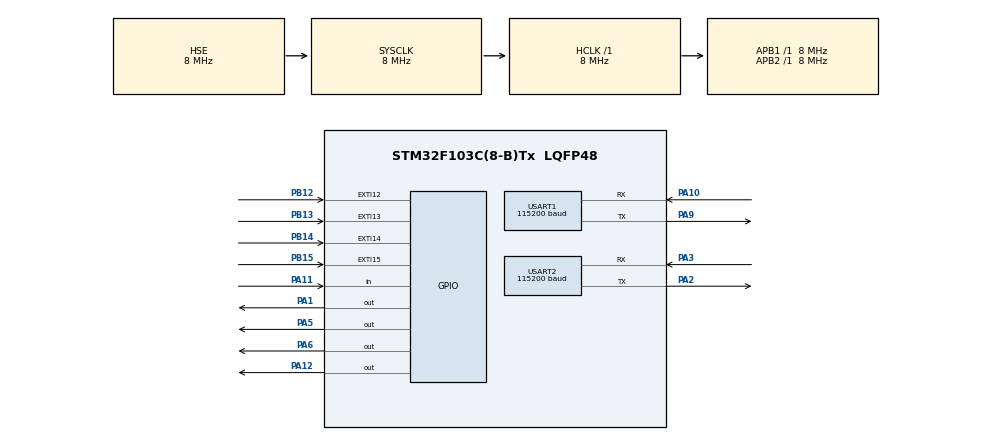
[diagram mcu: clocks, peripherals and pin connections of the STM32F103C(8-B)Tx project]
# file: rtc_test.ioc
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Mcu.Family=STM32F1
Mcu.Name=STM32F103C(8-B)Tx
Mcu.Package=LQFP48
NVIC.EXTI15_10_IRQn=true\:0\:0\:false
NVIC.PriorityGroup=NVIC_PRIORITYGROUP_4
NVIC.TIM2_IRQn=true\:0\:0\:false
NVIC.TIM3_IRQn=true\:0\:0\:false
NVIC.USART1_IRQn=true\:0\:0\:false
NVIC.USART2_IRQn=true\:1\:0\:true
PA1.Signal=GPIO_Output
PA10.GPIO_PuPd=GPIO_NOPULL
PA10.Mode=Asynchronous
PA10.Signal=USART1_RX
PA11.GPIO_PuPd=GPIO_PULLUP
PA11.Signal=GPIO_Input
PA12.GPIO_Speed=GPIO_SPEED_HIGH
PA12.Signal=GPIO_Output
PA2.Mode=Asynchronous
PA2.Signal=USART2_TX
PA3.GPIO_PuPd=GPIO_PULLUP
PA3.Mode=Asynchronous
PA3.Signal=USART2_RX
PA5.Signal=GPIO_Output
PA6.Signal=GPIO_Output
PA9.Mode=Asynchronous
PA9.Signal=USART1_TX
PB12.GPIO_PuPd=GPIO_PULLUP
PB12.Signal=GPXTI12
PB13.GPIO_PuPd=GPIO_PULLUP
PB13.Signal=GPXTI13
PB14.GPIO_PuPd=GPIO_PULLUP
PB14.Signal=GPXTI14
PB15.GPIO_PuPd=GPIO_PULLUP
PB15.Signal=GPXTI15
PC14-OSC32_IN.Mode=LSE-External-Oscillator
PC14-OSC32_IN.Signal=RCC_OSC32_IN
PC15-OSC32_OUT.Mode=LSE-External-Oscillator
PC15-OSC32_OUT.Signal=RCC_OSC32_OUT
PD0-OSC_IN.Mode=HSE-External-Oscillator
PD0-OSC_IN.Signal=RCC_OSC_IN
PD1-OSC_OUT.Mode=HSE-External-Oscillator
PD1-OSC_OUT.Signal=RCC_OSC_OUT
ProjectManager.TargetToolchain=EWARM
RCC.AHBFreq_Value=8000000
RCC.APB1Freq_Value=8000000
RCC.APB1TimFreq_Value=8000000
RCC.APB2Freq_Value=8000000
RCC.APB2TimFreq_Value=8000000
RCC.HCLKFreq_Value=8000000
RCC.HSIState=RCC_HSI_ON
RCC.PLLMUL=RCC_PLL_MUL9
RCC.PLLSourceVirtual=RCC_PLLSOURCE_HSE
RCC.RTCClockSelection=RCC_RTCCLKSOURCE_LSE
RCC.SYSCLKFreq_VALUE=8000000
RCC.SYSCLKSource=RCC_SYSCLKSOURCE_HSE
RCC.USBFreq_Value=72000000
TIM2.Period=4999
TIM2.Prescaler=7999
TIM2.TIM_MasterOutputTrigger=TIM_TRGO_UPDATE
TIM3.Period=1
TIM3.Prescaler=7999
TIM3.TIM_MasterOutputTrigger=TIM_TRGO_UPDATE
USART1.BaudRate=115200
USART2.BaudRate=115200
USART2.Parity=UART_PARITY_NONE
USART2.WordLength=UART_WORDLENGTH_8B
VP_RTC_No_RTC_Output.Mode=RTC OUT
VP_TIM2_VS_ClockSourceINT.Mode=Internal
VP_TIM3_VS_ClockSourceINT.Mode=Internal
board=rtc_test

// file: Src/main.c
/**
  ******************************************************************************
  * File Name          : main.c
  * Description        : Main program body
  ******************************************************************************
  *
  * COPYRIGHT(c) 2016 STMicroelectronics
  *
  * Redistribution and use in source and binary forms, with or without modification,
  * are permitted provided that the following conditions are met:
  *   1. Redistributions of source code must retain the above copyright notice,
  *      this list of conditions and the following disclaimer.
  *   2. Redistributions in binary form must reproduce the above copyright notice,
  *      this list of conditions and the following disclaimer in the documentation
  *      and/or other materials provided with the distribution.
  *   3. Neither the name of STMicroelectronics nor the names of its contributors
  *      may be used to endorse or promote products derived from this software
  *      without specific prior written permission.
  *
  * THIS SOFTWARE IS PROVIDED BY THE COPYRIGHT HOLDERS AND CONTRIBUTORS "AS IS"
  * AND ANY EXPRESS OR IMPLIED WARRANTIES, INCLUDING, BUT NOT LIMITED TO, THE
  * IMPLIED WARRANTIES OF MERCHANTABILITY AND FITNESS FOR A PARTICULAR PURPOSE ARE
  * DISCLAIMED. IN NO EVENT SHALL THE COPYRIGHT HOLDER OR CONTRIBUTORS BE LIABLE
  * FOR ANY DIRECT, INDIRECT, INCIDENTAL, SPECIAL, EXEMPLARY, OR CONSEQUENTIAL
  * DAMAGES (INCLUDING, BUT NOT LIMITED TO, PROCUREMENT OF SUBSTITUTE GOODS OR
  * SERVICES; LOSS OF USE, DATA, OR PROFITS; OR BUSINESS INTERRUPTION) HOWEVER
  * CAUSED AND ON ANY THEORY OF LIABILITY, WHETHER IN CONTRACT, STRICT LIABILITY,
  * OR TORT (INCLUDING NEGLIGENCE OR OTHERWISE) ARISING IN ANY WAY OUT OF THE USE
  * OF THIS SOFTWARE, EVEN IF ADVISED OF THE POSSIBILITY OF SUCH DAMAGE.
  *
  ******************************************************************************
  */
#include "stm32f1xx_hal.h"

RTC_HandleTypeDef hrtc;

TIM_HandleTypeDef htim2;
TIM_HandleTypeDef htim3;

UART_HandleTypeDef huart1;
UART_HandleTypeDef huart2;

/* USER CODE BEGIN PV */
/* Private variables ---------------------------------------------------------*/

/* USER CODE END PV */

void SystemClock_Config(void);
static void MX_GPIO_Init(void);
static void MX_RTC_Init(void);
static void MX_TIM2_Init(void);
static void MX_TIM3_Init(void);
static void MX_USART1_UART_Init(void);
static void MX_USART2_UART_Init(void);

/* USER CODE BEGIN PFP */
/* Private function prototypes -----------------------------------------------*/

/* USER CODE END PFP */

/* USER CODE BEGIN 0 */
RTC_TimeTypeDef myTime;
RTC_DateTypeDef myDate;
/* USER CODE END 0 */

int main(void)
{

  /* MCU Configuration----------------------------------------------------------*/

  /* Reset of all peripherals, Initializes the Flash interface and the Systick. */
  HAL_Init();

  /* Configure the system clock */
  SystemClock_Config();

  /* Initialize all configured peripherals */
  MX_GPIO_Init();
  MX_RTC_Init();
  //if(!(*(volatile uint32_t *) (BDCR_RTCEN_BB)))__HAL_RCC_RTC_ENABLE();
  MX_TIM2_Init();
  MX_TIM3_Init();
  MX_USART1_UART_Init();
  MX_USART2_UART_Init();

  /* Infinite loop */
  while (1)
  {

  /* USER CODE BEGIN 3 */
    HAL_RTC_GetTime(&hrtc, &myTime, FORMAT_BIN);
    HAL_RTC_GetDate(&hrtc, &myDate, FORMAT_BIN);
  }
  /* USER CODE END 3 */

}

/** System Clock Configuration
*/
void SystemClock_Config(void)
{

  RCC_OscInitTypeDef RCC_OscInitStruct;
  RCC_ClkInitTypeDef RCC_ClkInitStruct;
  RCC_PeriphCLKInitTypeDef PeriphClkInit;

  RCC_OscInitStruct.OscillatorType = RCC_OSCILLATORTYPE_HSE|RCC_OSCILLATORTYPE_LSE;
  RCC_OscInitStruct.HSEState = RCC_HSE_ON;
  RCC_OscInitStruct.LSEState = RCC_LSE_ON;
  RCC_OscInitStruct.PLL.PLLState = RCC_PLL_NONE;
  HAL_RCC_OscConfig(&RCC_OscInitStruct);

  RCC_ClkInitStruct.ClockType = RCC_CLOCKTYPE_SYSCLK;
  RCC_ClkInitStruct.SYSCLKSource = RCC_SYSCLKSOURCE_HSE;
  RCC_ClkInitStruct.AHBCLKDivider = RCC_SYSCLK_DIV1;
  RCC_ClkInitStruct.APB1CLKDivider = RCC_HCLK_DIV1;
  RCC_ClkInitStruct.APB2CLKDivider = RCC_HCLK_DIV1;
  HAL_RCC_ClockConfig(&RCC_ClkInitStruct, FLASH_LATENCY_0);

  PeriphClkInit.PeriphClockSelection = RCC_PERIPHCLK_RTC;
  PeriphClkInit.RTCClockSelection = RCC_RTCCLKSOURCE_LSE;
  HAL_RCCEx_PeriphCLKConfig(&PeriphClkInit);

  HAL_SYSTICK_Config(HAL_RCC_GetHCLKFreq()/1000);

  HAL_SYSTICK_CLKSourceConfig(SYSTICK_CLKSOURCE_HCLK);

  /* SysTick_IRQn interrupt configuration */
  HAL_NVIC_SetPriority(SysTick_IRQn, 0, 0);
}

/* RTC init function */
void MX_RTC_Init(void)
{

  RTC_TimeTypeDef sTime;
  RTC_DateTypeDef DateToUpdate;

    /**Initialize RTC and set the Time and Date
    */
  hrtc.Instance = RTC;
  hrtc.Init.AsynchPrediv = RTC_AUTO_1_SECOND;
  hrtc.Init.OutPut = RTC_OUTPUTSOURCE_NONE;
  HAL_RTC_Init(&hrtc);

  sTime.Hours = 0x1;
  sTime.Minutes = 0x0;
  sTime.Seconds = 0x0;

  HAL_RTC_SetTime(&hrtc, &sTime, FORMAT_BCD);

  DateToUpdate.WeekDay = RTC_WEEKDAY_MONDAY;
  DateToUpdate.Month = RTC_MONTH_JANUARY;
  DateToUpdate.Date = 0x1;
  DateToUpdate.Year = 0x0;

  HAL_RTC_SetDate(&hrtc, &DateToUpdate, FORMAT_BCD);

}

/* TIM2 init function */
void MX_TIM2_Init(void)
{

  TIM_ClockConfigTypeDef sClockSourceConfig;
  TIM_MasterConfigTypeDef sMasterConfig;

  htim2.Instance = TIM2;
  htim2.Init.Prescaler = 7999;
  htim2.Init.CounterMode = TIM_COUNTERMODE_UP;
  htim2.Init.Period = 4999;
  htim2.Init.ClockDivision = TIM_CLOCKDIVISION_DIV1;
  HAL_TIM_Base_Init(&htim2);

  sClockSourceConfig.ClockSource = TIM_CLOCKSOURCE_INTERNAL;
  HAL_TIM_ConfigClockSource(&htim2, &sClockSourceConfig);

  sMasterConfig.MasterOutputTrigger = TIM_TRGO_UPDATE;
  sMasterConfig.MasterSlaveMode = TIM_MASTERSLAVEMODE_DISABLE;
  HAL_TIMEx_MasterConfigSynchronization(&htim2, &sMasterConfig);

}

/* TIM3 init function */
void MX_TIM3_Init(void)
{

  TIM_ClockConfigTypeDef sClockSourceConfig;
  TIM_MasterConfigTypeDef sMasterConfig;

  htim3.Instance = TIM3;
  htim3.Init.Prescaler = 7999;
  htim3.Init.CounterMode = TIM_COUNTERMODE_UP;
  htim3.Init.Period = 1;
  htim3.Init.ClockDivision = TIM_CLOCKDIVISION_DIV1;
  HAL_TIM_Base_Init(&htim3);

  sClockSourceConfig.ClockSource = TIM_CLOCKSOURCE_INTERNAL;
  HAL_TIM_ConfigClockSource(&htim3, &sClockSourceConfig);

  sMasterConfig.MasterOutputTrigger = TIM_TRGO_UPDATE;
  sMasterConfig.MasterSlaveMode = TIM_MASTERSLAVEMODE_DISABLE;
  HAL_TIMEx_MasterConfigSynchronization(&htim3, &sMasterConfig);

}

/* USART1 init function */
void MX_USART1_UART_Init(void)
{

  huart1.Instance = USART1;
  huart1.Init.BaudRate = 115200;
  huart1.Init.WordLength = UART_WORDLENGTH_8B;
  huart1.Init.StopBits = UART_STOPBITS_1;
  huart1.Init.Parity = UART_PARITY_NONE;
  huart1.Init.Mode = UART_MODE_TX_RX;
  huart1.Init.HwFlowCtl = UART_HWCONTROL_NONE;
  huart1.Init.OverSampling = UART_OVERSAMPLING_16;
  HAL_UART_Init(&huart1);

}

/* USART2 init function */
void MX_USART2_UART_Init(void)
{

  huart2.Instance = USART2;
  huart2.Init.BaudRate = 115200;
  huart2.Init.WordLength = UART_WORDLENGTH_8B;
  huart2.Init.StopBits = UART_STOPBITS_1;
  huart2.Init.Parity = UART_PARITY_NONE;
  huart2.Init.Mode = UART_MODE_TX_RX;
  huart2.Init.HwFlowCtl = UART_HWCONTROL_NONE;
  huart2.Init.OverSampling = UART_OVERSAMPLING_16;
  HAL_UART_Init(&huart2);

}

/** Configure pins as
        * Analog
        * Input
        * Output
        * EVENT_OUT
        * EXTI
*/
void MX_GPIO_Init(void)
{

  GPIO_InitTypeDef GPIO_InitStruct;

  /* GPIO Ports Clock Enable */
  __GPIOC_CLK_ENABLE();
  __GPIOD_CLK_ENABLE();
  __GPIOA_CLK_ENABLE();
  __GPIOB_CLK_ENABLE();

  /*Configure GPIO pins : PA1 PA5 PA6 */
  GPIO_InitStruct.Pin = GPIO_PIN_1|GPIO_PIN_5|GPIO_PIN_6;
  GPIO_InitStruct.Mode = GPIO_MODE_OUTPUT_PP;
  GPIO_InitStruct.Speed = GPIO_SPEED_LOW;
  HAL_GPIO_Init(GPIOA, &GPIO_InitStruct);

  /*Configure GPIO pins : PB12 PB13 PB14 PB15 */
  GPIO_InitStruct.Pin = GPIO_PIN_12|GPIO_PIN_13|GPIO_PIN_14|GPIO_PIN_15;
  GPIO_InitStruct.Mode = GPIO_MODE_IT_RISING;
  GPIO_InitStruct.Pull = GPIO_PULLUP;
  HAL_GPIO_Init(GPIOB, &GPIO_InitStruct);

  /*Configure GPIO pin : PA11 */
  GPIO_InitStruct.Pin = GPIO_PIN_11;
  GPIO_InitStruct.Mode = GPIO_MODE_INPUT;
  GPIO_InitStruct.Pull = GPIO_PULLUP;
  HAL_GPIO_Init(GPIOA, &GPIO_InitStruct);

  /*Configure GPIO pin : PA12 */
  GPIO_InitStruct.Pin = GPIO_PIN_12;
  GPIO_InitStruct.Mode = GPIO_MODE_OUTPUT_PP;
  GPIO_InitStruct.Speed = GPIO_SPEED_HIGH;
  HAL_GPIO_Init(GPIOA, &GPIO_InitStruct);

  /* EXTI interrupt init*/
  HAL_NVIC_SetPriority(EXTI15_10_IRQn, 0, 0);
  HAL_NVIC_EnableIRQ(EXTI15_10_IRQn);

}

/************************ (C) COPYRIGHT STMicroelectronics *****END OF FILE****/
